# nrf51 register map
Vendor: Nordic Semiconductor; Series: nrf51; File version: 522
CPU: CM0 r3p1, little endian, no MPU, no FPU, 2 interrupt priority bits
Registers are 32-bit, read-write, reset 0x0 unless marked. A register's access mark holds for its fields unless they carry their own. Offsets are from the block's base; [hi:lo] are bit positions; {n}, {i} and the like mark numbered series.

## RADIO — The radio.
Base 0x40001000
0x00 TASKS_TXEN wo — Enable radio in TX mode.
0x04 TASKS_RXEN wo — Enable radio in RX mode.
0x08 TASKS_START wo — Start radio.
0x0C TASKS_STOP wo — Stop radio.
0x10 TASKS_DISABLE wo — Disable radio.
0x14 TASKS_RSSISTART wo — Start the RSSI and take one sample of the receive signal strength.
0x18 TASKS_RSSISTOP wo — Stop the RSSI measurement.
0x1C TASKS_BCSTART wo — Start the bit counter.
0x20 TASKS_BCSTOP wo — Stop the bit counter.
0x100 EVENTS_READY — Ready event.
0x104 EVENTS_ADDRESS — Address event.
0x108 EVENTS_PAYLOAD — Payload event.
0x10C EVENTS_END — End event.
0x110 EVENTS_DISABLED — Disable event.
0x114 EVENTS_DEVMATCH — A device address match occurred on the last received packet.
0x118 EVENTS_DEVMISS — No device address match occurred on the last received packet.
0x11C EVENTS_RSSIEND — Sampling of the receive signal strength complete. A new RSSI sample is ready for readout at the RSSISAMPLE register.
0x128 EVENTS_BCMATCH — Bit counter reached bit count value specified in BCC register.
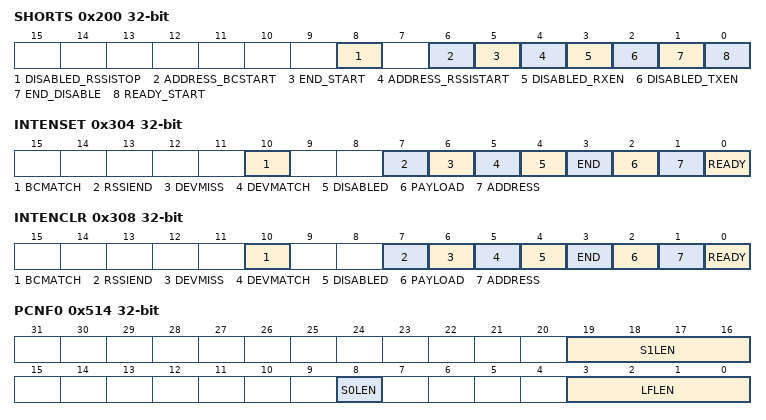
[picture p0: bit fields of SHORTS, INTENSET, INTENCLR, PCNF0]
0x200 SHORTS — Shortcuts for the radio.
  [all] fields
    0=Disabled (Shortcut disabled.); 1=Enabled (Shortcut enabled.)
  [8] DISABLED_RSSISTOP — Shortcut between DISABLED event and RSSISTOP task.
  [6] ADDRESS_BCSTART — Shortcut between ADDRESS event and BCSTART task.
  [5] END_START — Shortcut between END event and START task.
  [4] ADDRESS_RSSISTART — Shortcut between ADDRESS event and RSSISTART task.
  [3] DISABLED_RXEN — Shortcut between DISABLED event and RXEN task.
  [2] DISABLED_TXEN — Shortcut between DISABLED event and TXEN task.
  [1] END_DISABLE — Shortcut between END event and DISABLE task.
  [0] READY_START — Shortcut between READY event and START task.
0x304 INTENSET — Interrupt enable set register.
  [all] fields
    on read: 0=Disabled (Interrupt disabled.); 1=Enabled (Interrupt enabled.) | on write: 1=Set (Enable interrupt on write.)
  [10] BCMATCH — Enable interrupt on BCMATCH event.
  [7] RSSIEND — Enable interrupt on RSSIEND event.
  [6] DEVMISS — Enable interrupt on DEVMISS event.
  [5] DEVMATCH — Enable interrupt on DEVMATCH event.
  [4] DISABLED — Enable interrupt on DISABLED event.
  [3] END — Enable interrupt on END event.
  [2] PAYLOAD — Enable interrupt on PAYLOAD event.
  [1] ADDRESS — Enable interrupt on ADDRESS event.
  [0] READY — Enable interrupt on READY event.
0x308 INTENCLR — Interrupt enable clear register.
  [all] fields
    on read: 0=Disabled (Interrupt disabled.); 1=Enabled (Interrupt enabled.) | on write: 1=Clear (Disable interrupt on write.)
  [10] BCMATCH — Disable interrupt on BCMATCH event.
  [7] RSSIEND — Disable interrupt on RSSIEND event.
  [6] DEVMISS — Disable interrupt on DEVMISS event.
  [5] DEVMATCH — Disable interrupt on DEVMATCH event.
  [4] DISABLED — Disable interrupt on DISABLED event.
  [3] END — Disable interrupt on END event.
  [2] PAYLOAD — Disable interrupt on PAYLOAD event.
  [1] ADDRESS — Disable interrupt on ADDRESS event.
  [0] READY — Disable interrupt on READY event.
0x400 CRCSTATUS ro — CRC status of received packet.
  [0] CRCSTATUS
    0=CRCError (Packet received with CRC error.); 1=CRCOk (Packet received with CRC ok.)
0x408 RXMATCH ro — Received address.
  [2:0] RXMATCH — Logical address in which previous packet was received.
0x40C RXCRC ro — Received CRC.
  [23:0] RXCRC — CRC field of previously received packet.
0x410 DAI ro — Device address match index.
  [2:0] DAI — Index (n) of device address (see DAB[n] and DAP[n]) that obtained an address match.
0x504 PACKETPTR — Packet pointer. Decision point: START task.
0x508 FREQUENCY reset 0x2
  [6:0] FREQUENCY — Radio channel frequency offset in MHz: RF Frequency = 2400 + FREQUENCY (MHz). Decision point: TXEN or RXEN task.
0x50C TXPOWER — Output power.
  [7:0] TXPOWER — Radio output power. Decision point: TXEN task.
    4=Pos4dBm (+4dBm.); 0=0dBm; 252=Neg4dBm (-4dBm.); 248=Neg8dBm (-8dBm.); 244=Neg12dBm (-12dBm.); 240=Neg16dBm (-16dBm.); 236=Neg20dBm (-20dBm.); 216=Neg30dBm (-30dBm.)
0x510 MODE — Data rate and modulation.
  [1:0] MODE — Radio data rate and modulation setting. Decision point: TXEN or RXEN task.
    0=Nrf_1Mbit (1Mbit/s Nordic proprietary radio mode.); 1=Nrf_2Mbit (2Mbit/s Nordic proprietary radio mode.); 2=Nrf_250Kbit (250kbit/s Nordic proprietary radio mode.); 3=Ble_1Mbit (1Mbit/s Bluetooth Low Energy)
0x514 PCNF0 — Packet configuration 0.
  [19:16] S1LEN — Length of S1 field in number of bits. Decision point: START task.
  [8] S0LEN — Length of S0 field in number of bytes. Decision point: START task.
  [3:0] LFLEN — Length of length field in number of bits. Decision point: START task.
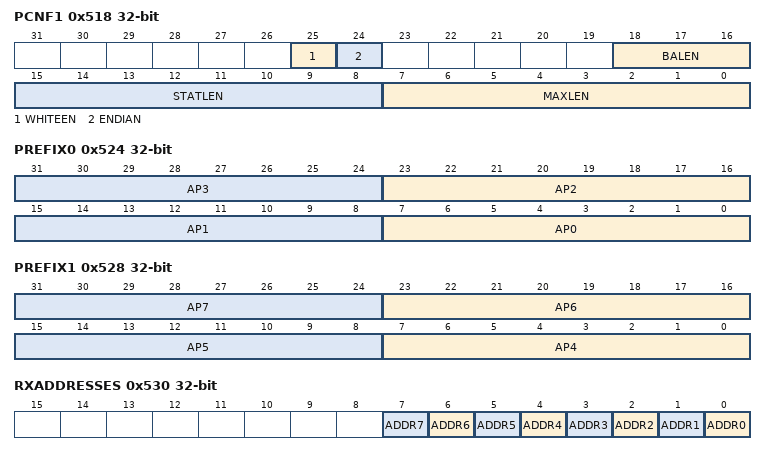
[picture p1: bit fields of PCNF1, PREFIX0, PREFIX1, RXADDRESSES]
0x518 PCNF1 — Packet configuration 1.
  [25] WHITEEN — Packet whitening enable.
    0=Disabled (Whitening disabled.); 1=Enabled (Whitening enabled.)
  [24] ENDIAN — On air endianness of packet length field. Decision point: START task.
    0=Little (Least significant bit on air first); 1=Big (Most significant bit on air first)
  [18:16] BALEN — Base address length in number of bytes. Decision point: START task.
  [15:8] STATLEN — Static length in number of bytes. Decision point: START task.
  [7:0] MAXLEN — Maximum length of packet payload in number of bytes.
0x51C BASE0 — Radio base address 0. Decision point: START task.
0x520 BASE1 — Radio base address 1. Decision point: START task.
0x524 PREFIX0 — Prefixes bytes for logical addresses 0 to 3.
  [8n+7:8n] AP{n} (n=0..3) — Address prefix {n}. Decision point: START task.
0x528 PREFIX1 — Prefixes bytes for logical addresses 4 to 7.
  [8n-25:8n-32] AP{n} (n=4..7) — Address prefix {n}. Decision point: START task.
0x52C TXADDRESS — Transmit address select.
  [2:0] TXADDRESS — Logical address to be used when transmitting a packet. Decision point: START task.
0x530 RXADDRESSES — Receive address select.
  [all] fields
    0=Disabled (Reception disabled.); 1=Enabled (Reception enabled.)
  [n] ADDR{n} (n=0..7) — Enable reception on logical address {n}. Decision point: START task.
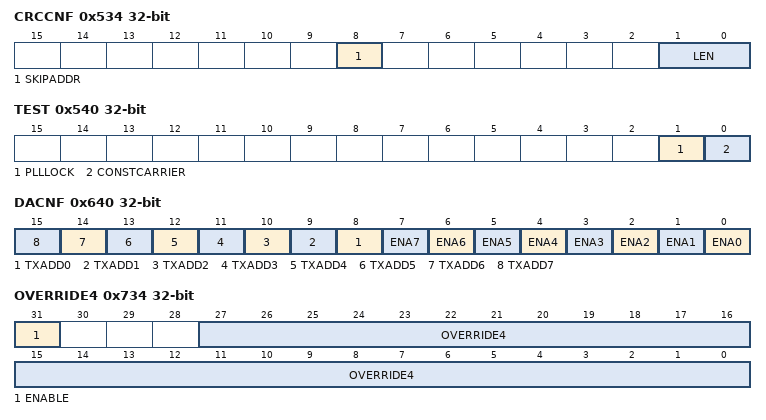
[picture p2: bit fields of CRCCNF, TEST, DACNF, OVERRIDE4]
0x534 CRCCNF — CRC configuration.
  [8] SKIPADDR — Leave packet address field out of the CRC calculation. Decision point: START task.
    0=Include packet address in CRC calculation; 1=Skip (Packet address is skipped in CRC calculation. The CRC calculation will start at the first byte after the address.)
  [1:0] LEN — CRC length. Decision point: START task.
    0=Disabled (CRC calculation disabled.); 1=One (One byte long CRC.); 2=Two (Two bytes long CRC.); 3=Three bytes long CRC
0x538 CRCPOLY — CRC polynomial.
  [23:0] CRCPOLY — CRC polynomial. Decision point: START task.
0x53C CRCINIT — CRC initial value.
  [23:0] CRCINIT — Initial value for CRC calculation. Decision point: START task.
0x540 TEST — Test features enable register.
  [1] PLLLOCK — PLL lock. Decision point: TXEN or RXEN task.
    0=Disabled (PLL lock disabled.); 1=Enabled (PLL lock enabled.)
  [0] CONSTCARRIER — Constant carrier. Decision point: TXEN task.
    0=Disabled (Constant carrier disabled.); 1=Enabled (Constant carrier enabled.)
0x544 TIFS — Inter Frame Spacing in microseconds.
  [7:0] TIFS — Inter frame spacing in microseconds. Decision point: START rask
0x548 RSSISAMPLE ro
  [6:0] RSSISAMPLE — RSSI sample result. The result is read as a positive value so that ReceivedSignalStrength = -RSSISAMPLE dBm
0x550 STATE ro — Current radio state.
  [3:0] STATE
    0=Disabled (Radio is in the Disabled state.); 1=RxRu (Radio is in the Rx Ramp Up state.); 2=RxIdle (Radio is in the Rx Idle state.); 3=Rx (Radio is in the Rx state.); 4=RxDisable (Radio is in the Rx Disable state.); 9=TxRu (Radio is in the Tx Ramp Up state.); 10=TxIdle (Radio is in the Tx Idle state.); 11=Tx (Radio is in the Tx state.); 12=TxDisable (Radio is in the Tx Disable state.)
0x554 DATAWHITEIV reset 0x40 — Data whitening initial value.
  [6:0] DATAWHITEIV — Data whitening initial value. Bit 0 corresponds to Position 0 of the LSFR, Bit 1 to position 5... Decision point: TXEN or RXEN task.
0x560 BCC — Bit counter compare.
{0x600+4i} DAB[{i}] (i=0..7) — Device address base segment.
{0x620+4i} DAP[{i}] (i=0..7) — Device address prefix.
  [15:0] DAP
0x640 DACNF — Device address match configuration.
  [n+8] TXADD{n} (n=0..7) — TxAdd for device address {n}.
  [n] ENA{n} (n=0..7) — Enable or disable device address matching using device address {n}.
    0=Disabled; 1=Enabled
{0x724+4i} OVERRIDE{i} (i=0..3) — Trim value override register {i}.
  [31:0] OVERRIDE{i} — Trim value override {i}.
0x734 OVERRIDE4 — Trim value override register 4.
  [31] ENABLE — Enable or disable override of default trim values.
    0=Disabled (Override trim values disabled.); 1=Enabled (Override trim values enabled.)
  [27:0] OVERRIDE4 — Trim value override 4.
0xFFC POWER — Peripheral power control.
  [0] POWER
    0=Disabled (Module power disabled.); 1=Enabled (Module power enabled.)

## Notices in the file
Copyright (c) 2010 - 2018, Nordic Semiconductor ASA All rights reserved.
Redistribution and use in source and binary forms, with or without
modification, are permitted provided that the following conditions are met:
1. Redistributions of source code must retain the above copyright notice, this
list of conditions and the following disclaimer.
2. Redistributions in binary form must reproduce the above copyright
notice, this list of conditions and the following disclaimer in the
documentation and/or other materials provided with the distribution.
3. Neither the name of Nordic Semiconductor ASA nor the names of its
contributors may be used to endorse or promote products derived from this
software without specific prior written permission.
THIS SOFTWARE IS PROVIDED BY THE COPYRIGHT HOLDERS AND CONTRIBUTORS "AS IS"
AND ANY EXPRESS OR IMPLIED WARRANTIES, INCLUDING, BUT NOT LIMITED TO, THE
IMPLIED WARRANTIES OF MERCHANTABILITY, AND FITNESS FOR A PARTICULAR PURPOSE
ARE DISCLAIMED. IN NO EVENT SHALL NORDIC SEMICONDUCTOR ASA OR CONTRIBUTORS BE
LIABLE FOR ANY DIRECT, INDIRECT, INCIDENTAL, SPECIAL, EXEMPLARY, OR
CONSEQUENTIAL DAMAGES (INCLUDING, BUT NOT LIMITED TO, PROCUREMENT OF
SUBSTITUTE GOODS OR SERVICES; LOSS OF USE, DATA, OR PROFITS; OR BUSINESS
INTERRUPTION) HOWEVER CAUSED AND ON ANY THEORY OF LIABILITY, WHETHER IN
CONTRACT, STRICT LIABILITY, OR TORT (INCLUDING NEGLIGENCE OR OTHERWISE)
ARISING IN ANY WAY OUT OF THE USE OF THIS SOFTWARE, EVEN IF ADVISED OF THE
POSSIBILITY OF SUCH DAMAGE.
